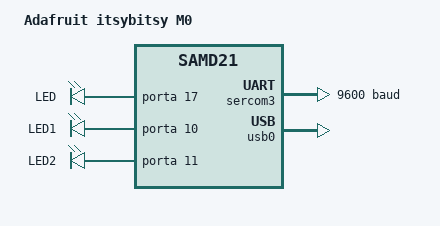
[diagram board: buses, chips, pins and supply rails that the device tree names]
/*
 * Copyright (c) 2018 Google LLC.
 *
 * SPDX-License-Identifier: Apache-2.0
 */

/dts-v1/;
#include <atmel/samd21.dtsi>

/ {
	model = "Adafruit itsybitsy M0";
	compatible = "adafruit,itsybitsy-m0", "atmel,samd21e18a", "atmel,samd21";

	chosen {
		zephyr,console = &sercom3;
		zephyr,shell-uart = &sercom3;
		zephyr,sram = &sram0;
		zephyr,flash = &flash0;
	};

	/* These aliases are provided for compatibility with samples */
	aliases {
		led0 = &led0;
    led1 = &led1;
    led2 = &led2;
	};

	leds {
		compatible = "gpio-leds";

		led0: led_0 {
			gpios = <&porta 17 GPIO_ACTIVE_HIGH>;
			label = "LED";
		};

    led1: led_1 {
			gpios = <&porta 10 GPIO_ACTIVE_HIGH>;
			label = "LED1";
		};

    led2: led_2 {
			gpios = <&porta 11 GPIO_ACTIVE_HIGH>;
			label = "LED2";
		};

    };
};

&cpu0 {
	clock-frequency = <48000000>;
};



/*
&sercom0 {
	status = "okay";
	compatible = "atmel,sam0-uart";
	current-speed = <115200>;
	rxpo = <3>;
	txpo = <2>;
};
*/

&sercom3 {
	status = "okay";
	compatible = "atmel,sam0-uart";
	current-speed = <9600>;
	rxpo = <2>;
	txpo = <3>;
};


&usb0 {
	status = "okay";
};
